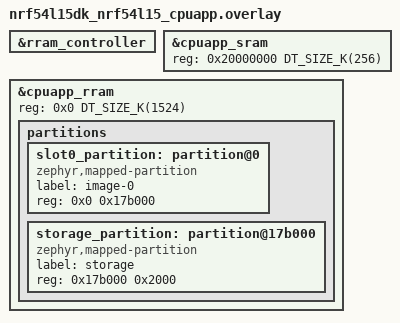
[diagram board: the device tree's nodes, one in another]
/*
 * Copyright (c) 2024 Nordic Semiconductor ASA
 *
 * SPDX-License-Identifier: LicenseRef-Nordic-5-Clause
 */

/delete-node/ &boot_partition;
/delete-node/ &slot0_partition;
/delete-node/ &slot1_partition;
/delete-node/ &storage_partition;

&rram_controller {
	/delete-node/ cpuflpr_sram;
	/delete-node/ cpuflpr_rram;
};

/* Adjust the cpuapp_sram to include the freed up cpuflpr_sram */
&cpuapp_sram {
	reg = <0x20000000 DT_SIZE_K(256)>;
	ranges = <0x0 0x20000000 0x20040000>;
};

/* Adjust the cpuapp_rram to include the freed up cpuflpr_rram */
&cpuapp_rram {
	reg = <0x0 DT_SIZE_K(1524)>;

	partitions {
		slot0_partition: partition@0 {
			compatible = "zephyr,mapped-partition";
			label = "image-0";
			reg = <0x0 0x17b000>;
		};

		storage_partition: partition@17b000 {
			compatible = "zephyr,mapped-partition";
			label = "storage";
			reg = <0x17b000 0x2000>;
		};
	};
};
